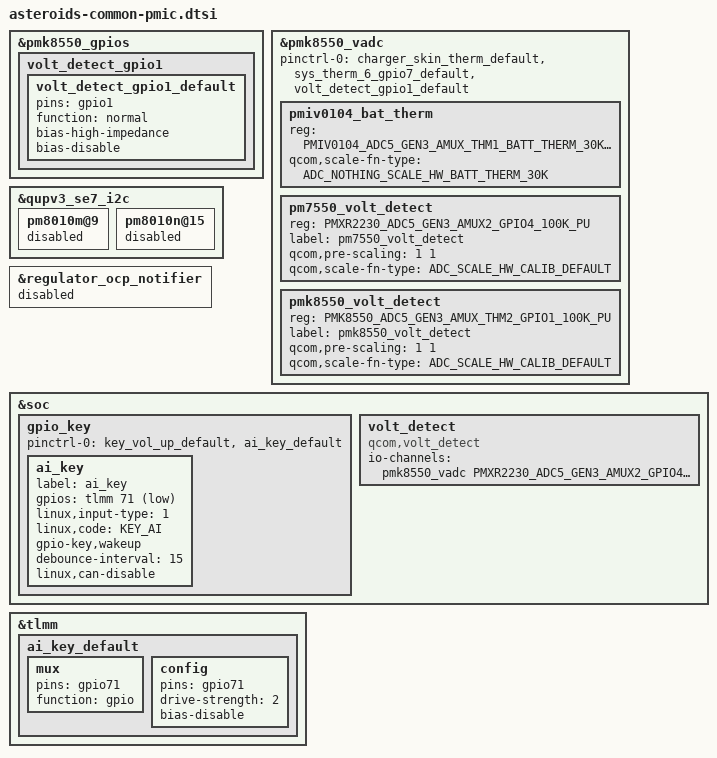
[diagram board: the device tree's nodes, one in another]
#include <dt-bindings/iio/qcom,spmi-adc5-gen3-pmiv0104.h>
#include <dt-bindings/iio/qcom,spmi-adc5-gen3-pmk8550.h>
#include <dt-bindings/iio/qcom,spmi-adc5-gen3-pmxr2230.h>
#include <dt-bindings/iio/qcom,spmi-vadc.h>
#include <dt-bindings/input/input.h>

&pmk8550_gpios {
	volt_detect_gpio1 {
		volt_detect_gpio1_default: volt_detect_gpio1_default {
			pins = "gpio1";
			function = "normal";
			bias-high-impedance;
			bias-disable;
		};
	};
};

&pmk8550_vadc {
	pinctrl-0 = <&charger_skin_therm_default &sys_therm_6_gpio7_default &volt_detect_gpio1_default>;

	pmiv0104_bat_therm {
		reg = <PMIV0104_ADC5_GEN3_AMUX_THM1_BATT_THERM_30K_PU>;
		qcom,scale-fn-type = <ADC_NOTHING_SCALE_HW_BATT_THERM_30K>;
	};

	pm7550_volt_detect {
		reg = <PMXR2230_ADC5_GEN3_AMUX2_GPIO4_100K_PU>;
		label = "pm7550_volt_detect";
		qcom,pre-scaling = <1 1>;
		qcom,scale-fn-type = <ADC_SCALE_HW_CALIB_DEFAULT>;
	};

	pmk8550_volt_detect {
		reg = <PMK8550_ADC5_GEN3_AMUX_THM2_GPIO1_100K_PU>;
		label = "pmk8550_volt_detect";
		qcom,pre-scaling = <1 1>;
		qcom,scale-fn-type = <ADC_SCALE_HW_CALIB_DEFAULT>;
	};
};

&qupv3_se7_i2c {
	pm8010m@9 {
		status = "disabled";
	};

	pm8010n@15 {
		status = "disabled";
	};
};

&regulator_ocp_notifier {
	status = "disabled";
};

&soc {
	gpio_key {
		pinctrl-0 = <&key_vol_up_default &ai_key_default>;

		ai_key {
			label = "ai_key";
			gpios = <&tlmm 71 GPIO_ACTIVE_LOW>;
			linux,input-type = <1>;
			linux,code = <KEY_AI>;
			gpio-key,wakeup;
			debounce-interval = <15>;
			linux,can-disable;
		};
	};

	volt_detect {
		compatible = "qcom,volt_detect";
		io-channels = <&pmk8550_vadc PMXR2230_ADC5_GEN3_AMUX2_GPIO4_100K_PU>;
		io-channel-names = "gpio4_voltage";
	};
};

&tlmm {
	ai_key_default:ai_key_default {
		mux {
			pins = "gpio71";
			function = "gpio";
		};
		config {
			pins = "gpio71";
			drive-strength = <2>;
			bias-disable;
		};
	};
};

#include "wl28681.dtsi"
